AUTOSAR XML (schema 4-2-1)
package /RootP_ASWC_M413
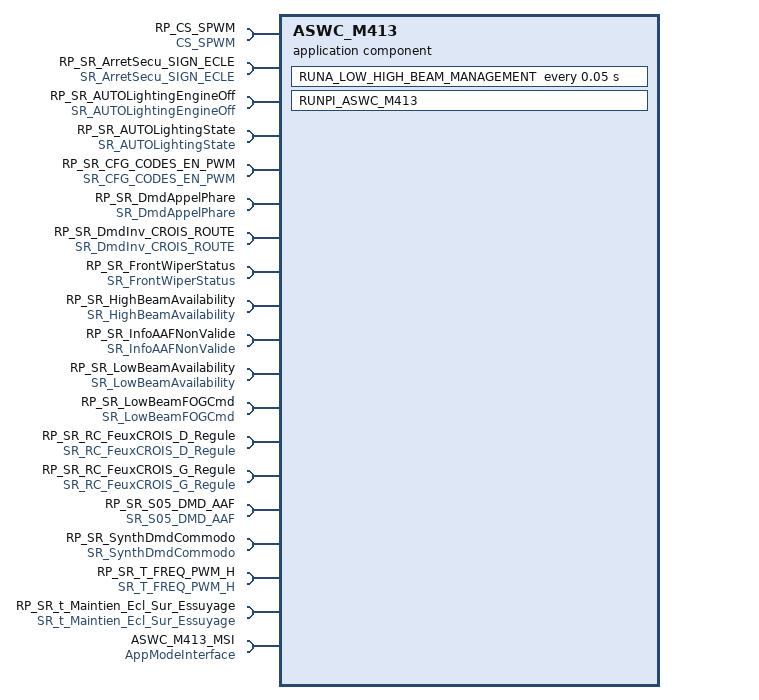
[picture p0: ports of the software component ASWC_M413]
  application sw component type ASWC_M413
    provide/require port PRP_SR_HeadLampFlashCmd: nonqueued-receiver-com-spec{data-element=HeadLampFlashCmd, enable-update=0, handle-data-status=1, handle-never-received=0, init-value=CONST_tLOG_0:0}, provided-required-interface=SR_HeadLampFlashCmd
    provide/require port PRP_SR_HighBeamCmd: nonqueued-receiver-com-spec{data-element=HighBeamCmd, enable-update=0, handle-data-status=1, handle-never-received=0, init-value=CONST_tLOG_0:0}, provided-required-interface=SR_HighBeamCmd
    provide/require port PRP_SR_LowBeamCmd: nonqueued-receiver-com-spec{data-element=LowBeamCmd, enable-update=0, handle-data-status=1, handle-never-received=0, init-value=CONST_tLOG_0:0}, provided-required-interface=SR_LowBeamCmd
    19 x require port:
      RP_CS_SPWM: required-interface=CS_SPWM
      RP_SR_ArretSecu_SIGN_ECLE: nonqueued-receiver-com-spec{data-element=ArretSecu_SIGN_ECLE, enable-update=0, handle-data-status=1, handle-never-received=0, init-value=CONST_tLOG_1:1}, required-interface=SR_ArretSecu_SIGN_ECLE
      RP_SR_AUTOLightingEngineOff: nonqueued-receiver-com-spec{data-element=AUTOLightingEngineOff, enable-update=0, handle-data-status=1, handle-never-received=0, init-value=CONST_tLOG_0:0}, required-interface=SR_AUTOLightingEngineOff
      RP_SR_AUTOLightingState: nonqueued-receiver-com-spec{data-element=AUTOLightingState, enable-update=0, handle-data-status=1, handle-never-received=0, init-value=CONST_tLOG_0:0}, required-interface=SR_AUTOLightingState
      RP_SR_CFG_CODES_EN_PWM: nonqueued-receiver-com-spec{data-element=CFG_CODES_EN_PWM, enable-update=0, handle-data-status=1, handle-never-received=0, init-value=CONST_tBYTE_1:1}, required-interface=SR_CFG_CODES_EN_PWM
      RP_SR_DmdAppelPhare: nonqueued-receiver-com-spec{data-element=DmdAppelPhare, enable-update=0, handle-data-status=1, handle-never-received=0, init-value=CONST_tLOG_0:0}, required-interface=SR_DmdAppelPhare
      RP_SR_DmdInv_CROIS_ROUTE: nonqueued-receiver-com-spec{data-element=DmdInv_CROIS_ROUTE, enable-update=0, handle-data-status=1, handle-never-received=0, init-value=CONST_tLOG_0:0}, required-interface=SR_DmdInv_CROIS_ROUTE
      RP_SR_FrontWiperStatus: nonqueued-receiver-com-spec{data-element=FrontWiperConfirmedStatus, enable-update=0, handle-data-status=1, handle-never-received=0, init-value=CONST_tLOG_0:0}, required-interface=SR_FrontWiperStatus
      RP_SR_HighBeamAvailability: nonqueued-receiver-com-spec{data-element=HighBeamAvailability, enable-update=0, handle-data-status=1, handle-never-received=0, init-value=CONST_tLOG_0:0}, required-interface=SR_HighBeamAvailability
      RP_SR_InfoAAFNonValide: nonqueued-receiver-com-spec{data-element=InfoAAFNonValide, enable-update=0, handle-data-status=1, handle-never-received=0, init-value=CONST_tLOG_0:0}, required-interface=SR_InfoAAFNonValide
      RP_SR_LowBeamAvailability: nonqueued-receiver-com-spec{data-element=LowBeamAvailability, enable-update=0, handle-data-status=1, handle-never-received=0, init-value=CONST_tLOG_0:0}, required-interface=SR_LowBeamAvailability
      RP_SR_LowBeamFOGCmd: nonqueued-receiver-com-spec{data-element=LowBeamFOGCmd, enable-update=0, handle-data-status=1, handle-never-received=0, init-value=CONST_tLOG_0:0}, required-interface=SR_LowBeamFOGCmd
      RP_SR_RC_FeuxCROIS_D_Regule: nonqueued-receiver-com-spec{data-element=RC_FeuxCROIS_D_Regule, enable-update=0, handle-data-status=1, handle-never-received=0, init-value=CONST_tBYTE_100:100}, required-interface=SR_RC_FeuxCROIS_D_Regule
      RP_SR_RC_FeuxCROIS_G_Regule: nonqueued-receiver-com-spec{data-element=RC_FeuxCROIS_G_Regule, enable-update=0, handle-data-status=1, handle-never-received=0, init-value=CONST_tBYTE_100:100}, required-interface=SR_RC_FeuxCROIS_G_Regule
      RP_SR_S05_DMD_AAF: nonqueued-receiver-com-spec{data-element=S05_DMD_AAF, enable-update=0, handle-data-status=1, handle-never-received=0, init-value=CONST_tLOG_0:0}, required-interface=SR_S05_DMD_AAF
      RP_SR_SynthDmdCommodo: nonqueued-receiver-com-spec{data-element=SynthDmdCommodo, enable-update=0, handle-data-status=1, handle-never-received=0, init-value=CONST_tBYTE_0:0}, required-interface=SR_SynthDmdCommodo
      RP_SR_T_FREQ_PWM_H: nonqueued-receiver-com-spec{data-element=T_FREQ_PWM_H, enable-update=0, handle-data-status=1, handle-never-received=0, init-value=CONST_tWORD_7:7}, required-interface=SR_T_FREQ_PWM_H
      RP_SR_t_Maintien_Ecl_Sur_Essuyage: nonqueued-receiver-com-spec{data-element=t_Maintien_Ecl_Sur_Essuyage, enable-update=0, handle-data-status=1, handle-never-received=0, init-value=CONST_tWORD_300:300}, required-interface=SR_t_Maintien_Ecl_Sur_Essuyage
      ASWC_M413_MSI: required-interface=AppModeInterface
    behavior IB_ASWC_M413: data-type-mapping=ApplicationModeMapping, handle-termination-and-restart=NO-SUPPORT
      ar-typed-per-instance-memorys:
        4 x data:
          PIM_M413_DmdInvCROISROUTE_Prec: type=tLOG, init-value=CONST_tLOG_0:0
          PIM_M413_LowBeamCmd_Prec: type=tLOG, init-value=CONST_tLOG_0:0
          PIM_M413_LowBeamFailureMode: type=tBYTE, init-value=CONST_tBYTE_0:0
          PIM_M413_T_MaintienEclEssuyage_Prec: type=tDWORD, init-value=CONST_tDWORD_0:0
      timing event RUNA_LOW_HIGH_BEAM_MANAGEMENT_Cyclic: start-on-event=RUNA_LOW_HIGH_BEAM_MANAGEMENT, period=0.05
        disabled-mode:
          ASWC_M413_MSI.AppMode.APP_WAKEUP
          ASWC_M413_MSI.AppMode.APP_OFF
          ASWC_M413_MSI.AppMode.APP_SYNC_INIT
          ASWC_M413_MSI.AppMode.APP_CONFIG
      swc mode switch event RUNPI_ASWC_M413_ENTRY: start-on-event=RUNPI_ASWC_M413, activation=ON-ENTRY, mode=ASWC_M413_MSI.AppMode.APP_WAKEUP
      runnable RUNA_LOW_HIGH_BEAM_MANAGEMENT
        data-read-access:
          20 x access:
            dra_RP_SR_ArretSecu_SIGN_ECLE_ArretSecu_SIGN_ECLE: accessed-variable=RP_SR_ArretSecu_SIGN_ECLE.ArretSecu_SIGN_ECLE
            dra_RP_SR_AUTOLightingEngineOff_AUTOLightingEngineOff: accessed-variable=RP_SR_AUTOLightingEngineOff.AUTOLightingEngineOff
            dra_RP_SR_AUTOLightingState_AUTOLightingState: accessed-variable=RP_SR_AUTOLightingState.AUTOLightingState
            dra_RP_SR_DmdAppelPhare_DmdAppelPhare: accessed-variable=RP_SR_DmdAppelPhare.DmdAppelPhare
            dra_RP_SR_DmdInv_CROIS_ROUTE_DmdInv_CROIS_ROUTE: accessed-variable=RP_SR_DmdInv_CROIS_ROUTE.DmdInv_CROIS_ROUTE
            dra_RP_SR_FrontWiperStatus_FrontWiperConfirmedStatus: accessed-variable=RP_SR_FrontWiperStatus.FrontWiperConfirmedStatus
            dra_RP_SR_HighBeamAvailability_HighBeamAvailability: accessed-variable=RP_SR_HighBeamAvailability.HighBeamAvailability
            dra_RP_SR_InfoAAFNonValide_InfoAAFNonValide: accessed-variable=RP_SR_InfoAAFNonValide.InfoAAFNonValide
            dra_RP_SR_LowBeamAvailability_LowBeamAvailability: accessed-variable=RP_SR_LowBeamAvailability.LowBeamAvailability
            dra_RP_SR_LowBeamFOGCmd_LowBeamFOGCmd: accessed-variable=RP_SR_LowBeamFOGCmd.LowBeamFOGCmd
            dra_RP_SR_S05_DMD_AAF_S05_DMD_AAF: accessed-variable=RP_SR_S05_DMD_AAF.S05_DMD_AAF
            dra_RP_SR_SynthDmdCommodo_SynthDmdCommodo: accessed-variable=RP_SR_SynthDmdCommodo.SynthDmdCommodo
            dra_RP_SR_CFG_CODES_EN_PWM_CFG_CODES_EN_PWM: accessed-variable=RP_SR_CFG_CODES_EN_PWM.CFG_CODES_EN_PWM
            dra_RP_SR_RC_FeuxCROIS_D_Regule_RC_FeuxCROIS_D_Regule: accessed-variable=RP_SR_RC_FeuxCROIS_D_Regule.RC_FeuxCROIS_D_Regule
            dra_RP_SR_RC_FeuxCROIS_G_Regule_RC_FeuxCROIS_G_Regule: accessed-variable=RP_SR_RC_FeuxCROIS_G_Regule.RC_FeuxCROIS_G_Regule
            dra_RP_SR_T_FREQ_PWM_H_T_FREQ_PWM_H: accessed-variable=RP_SR_T_FREQ_PWM_H.T_FREQ_PWM_H
            dra_RP_SR_t_Maintien_Ecl_Sur_Essuyage_t_Maintien_Ecl_Sur_Essuyage: accessed-variable=RP_SR_t_Maintien_Ecl_Sur_Essuyage.t_Maintien_Ecl_Sur_Essuyage
            dra_PRP_SR_HeadLampFlashCmd_HeadLampFlashCmd: accessed-variable=PRP_SR_HeadLampFlashCmd.HeadLampFlashCmd
            dra_PRP_SR_HighBeamCmd_HighBeamCmd: accessed-variable=PRP_SR_HighBeamCmd.HighBeamCmd
            dra_PRP_SR_LowBeamCmd_LowBeamCmd: accessed-variable=PRP_SR_LowBeamCmd.LowBeamCmd
        data-write-access:
          access dwa_PRP_SR_HeadLampFlashCmd_HeadLampFlashCmd: accessed-variable=PRP_SR_HeadLampFlashCmd.HeadLampFlashCmd
          access dwa_PRP_SR_HighBeamCmd_HighBeamCmd: accessed-variable=PRP_SR_HighBeamCmd.HighBeamCmd
          access dwa_PRP_SR_LowBeamCmd_LowBeamCmd: accessed-variable=PRP_SR_LowBeamCmd.LowBeamCmd
        sync call sscp_RUNA_LOW_HIGH_BEAM_MANAGEMENT_CS_SPWM_Set: operation=RP_CS_SPWM.Set, timeout=0
      runnable RUNPI_ASWC_M413
package /RootP_Implementatation
  swc implementation Implementatation_ASWC_M413: programming-language=C, sw-version=1.0.0, vendor-id=1, behavior=IB_ASWC_M413
    code-descriptors:
      code SRC: artifact-descriptors=autosar-engineering-object={short-label=EngObject, category=SWSRC}
    resource consumption Resources
